# MSS_CTRL_MSS_CTRL_50D00000h register map
Vendor: Texas Instruments
Registers are 32-bit, read-only, reset values left out (the file's numbers can be read two ways) unless marked. A register's access mark holds for its fields unless they carry their own. Offsets are as the file gives them; [hi:lo] are bit positions; {n}, {i} and the like mark numbered series.

## MSS_CTRL (part 3 of 10)
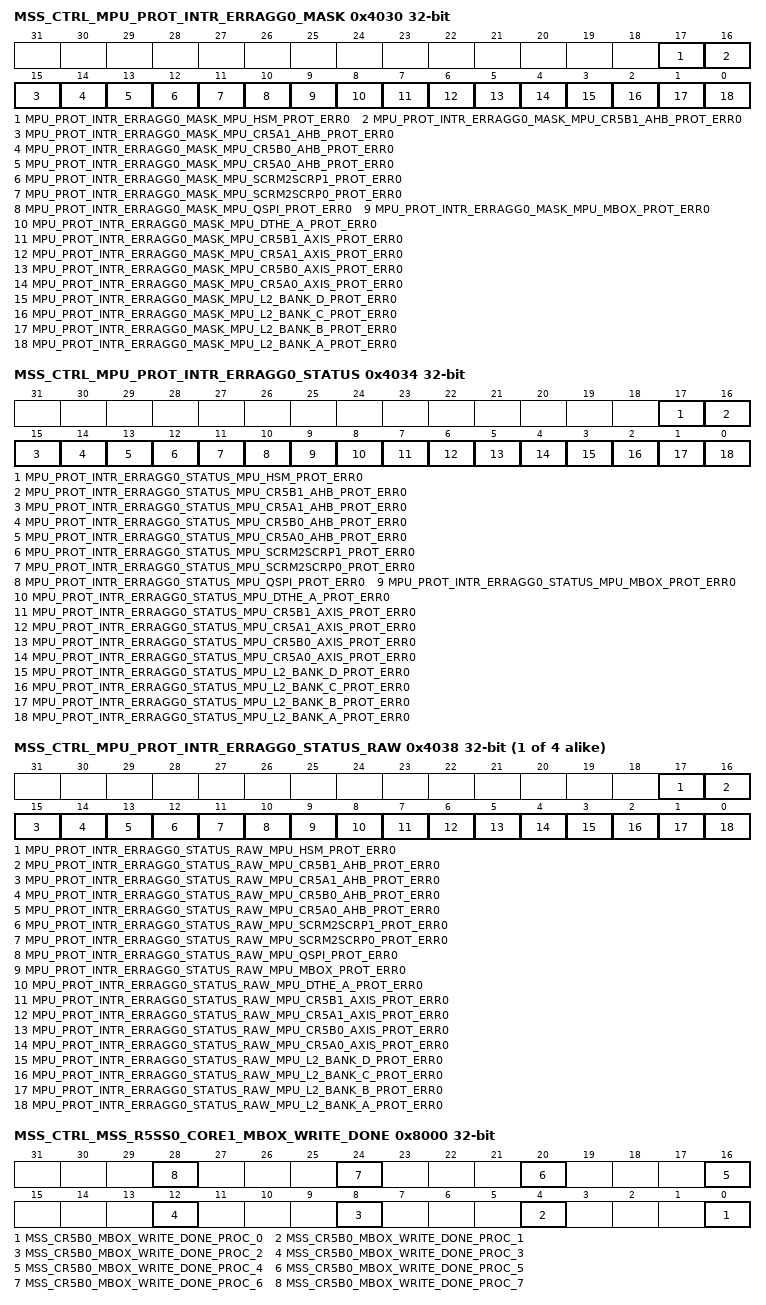
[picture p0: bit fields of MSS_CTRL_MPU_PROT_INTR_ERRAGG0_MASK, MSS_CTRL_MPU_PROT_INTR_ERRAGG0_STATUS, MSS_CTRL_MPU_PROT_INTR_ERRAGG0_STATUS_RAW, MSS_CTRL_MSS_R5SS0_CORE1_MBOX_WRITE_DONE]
0x4030 MSS_CTRL_MPU_PROT_INTR_ERRAGG0_MASK rw — This register Masks selected interrupt soures from generating MPU Protection Error Interrupt to R5SS0 CORE0 .
  [17] MPU_PROT_INTR_ERRAGG0_MASK_MPU_HSM_PROT_ERR0 — Mask Error from MPU_PROT_INTR to aggregated Error MPU_PROT_INTR_ERRAGG1'b1 : Error is Masked1'b0 : Error is Unmasked
  [16] MPU_PROT_INTR_ERRAGG0_MASK_MPU_CR5B1_AHB_PROT_ERR0 — Mask Error from MPU_PROT_INTR to aggregated Error MPU_PROT_INTR_ERRAGG1'b1 : Error is Masked1'b0 : Error is Unmasked
  [15] MPU_PROT_INTR_ERRAGG0_MASK_MPU_CR5A1_AHB_PROT_ERR0 — Mask Error from MPU_PROT_INTR to aggregated Error MPU_PROT_INTR_ERRAGG1'b1 : Error is Masked1'b0 : Error is Unmasked
  [14] MPU_PROT_INTR_ERRAGG0_MASK_MPU_CR5B0_AHB_PROT_ERR0 — Mask Error from MPU_PROT_INTR to aggregated Error MPU_PROT_INTR_ERRAGG1'b1 : Error is Masked1'b0 : Error is Unmasked
  [13] MPU_PROT_INTR_ERRAGG0_MASK_MPU_CR5A0_AHB_PROT_ERR0 — Mask Error from MPU_PROT_INTR to aggregated Error MPU_PROT_INTR_ERRAGG1'b1 : Error is Masked1'b0 : Error is Unmasked
  [12] MPU_PROT_INTR_ERRAGG0_MASK_MPU_SCRM2SCRP1_PROT_ERR0 — Mask Error from MPU_PROT_INTR to aggregated Error MPU_PROT_INTR_ERRAGG1'b1 : Error is Masked1'b0 : Error is Unmasked
  [11] MPU_PROT_INTR_ERRAGG0_MASK_MPU_SCRM2SCRP0_PROT_ERR0 — Mask Error from MPU_PROT_INTR to aggregated Error MPU_PROT_INTR_ERRAGG1'b1 : Error is Masked1'b0 : Error is Unmasked
  [10] MPU_PROT_INTR_ERRAGG0_MASK_MPU_QSPI_PROT_ERR0 — Mask Error from MPU_PROT_INTR to aggregated Error MPU_PROT_INTR_ERRAGG1'b1 : Error is Masked1'b0 : Error is Unmasked
  [9] MPU_PROT_INTR_ERRAGG0_MASK_MPU_MBOX_PROT_ERR0 — Mask Error from MPU_PROT_INTR to aggregated Error MPU_PROT_INTR_ERRAGG1'b1 : Error is Masked1'b0 : Error is Unmasked
  [8] MPU_PROT_INTR_ERRAGG0_MASK_MPU_DTHE_A_PROT_ERR0 — Mask Error from MPU_PROT_INTR to aggregated Error MPU_PROT_INTR_ERRAGG1'b1 : Error is Masked1'b0 : Error is Unmasked
  [7] MPU_PROT_INTR_ERRAGG0_MASK_MPU_CR5B1_AXIS_PROT_ERR0 — Mask Error from MPU_PROT_INTR to aggregated Error MPU_PROT_INTR_ERRAGG1'b1 : Error is Masked1'b0 : Error is Unmasked
  [6] MPU_PROT_INTR_ERRAGG0_MASK_MPU_CR5A1_AXIS_PROT_ERR0 — Mask Error from MPU_PROT_INTR to aggregated Error MPU_PROT_INTR_ERRAGG1'b1 : Error is Masked1'b0 : Error is Unmasked
  [5] MPU_PROT_INTR_ERRAGG0_MASK_MPU_CR5B0_AXIS_PROT_ERR0 — Mask Error from MPU_PROT_INTR to aggregated Error MPU_PROT_INTR_ERRAGG1'b1 : Error is Masked1'b0 : Error is Unmasked
  [4] MPU_PROT_INTR_ERRAGG0_MASK_MPU_CR5A0_AXIS_PROT_ERR0 — Mask Error from MPU_PROT_INTR to aggregated Error MPU_PROT_INTR_ERRAGG1'b1 : Error is Masked1'b0 : Error is Unmasked
  [3] MPU_PROT_INTR_ERRAGG0_MASK_MPU_L2_BANK_D_PROT_ERR0 — Mask Error from MPU_PROT_INTR to aggregated Error MPU_PROT_INTR_ERRAGG1'b1 : Error is Masked1'b0 : Error is Unmasked
  [2] MPU_PROT_INTR_ERRAGG0_MASK_MPU_L2_BANK_C_PROT_ERR0 — Mask Error from MPU_PROT_INTR to aggregated Error MPU_PROT_INTR_ERRAGG1'b1 : Error is Masked1'b0 : Error is Unmasked
  [1] MPU_PROT_INTR_ERRAGG0_MASK_MPU_L2_BANK_B_PROT_ERR0 — Mask Error from MPU_PROT_INTR to aggregated Error MPU_PROT_INTR_ERRAGG1'b1 : Error is Masked1'b0 : Error is Unmasked
  [0] MPU_PROT_INTR_ERRAGG0_MASK_MPU_L2_BANK_A_PROT_ERR0 — Mask Error from MPU_PROT_INTR to aggregated Error MPU_PROT_INTR_ERRAGG1'b1 : Error is Masked1'b0 : Error is Unmasked
0x4034 MSS_CTRL_MPU_PROT_INTR_ERRAGG0_STATUS rw — This register shows the Status of Unmasked MPU Protection Errors to R5SS0 Core0 .
  [17] MPU_PROT_INTR_ERRAGG0_STATUS_MPU_HSM_PROT_ERR0 — Status of Error from MPU_PROT_INTR. Set only if Interupt is unmasked in MPU_PROT_INTR_ERRAGG_MASKWrie 0x1 to clear this Error.
  [16] MPU_PROT_INTR_ERRAGG0_STATUS_MPU_CR5B1_AHB_PROT_ERR0 — Status of Error from MPU_PROT_INTR. Set only if Interupt is unmasked in MPU_PROT_INTR_ERRAGG_MASKWrie 0x1 to clear this Error.
  [15] MPU_PROT_INTR_ERRAGG0_STATUS_MPU_CR5A1_AHB_PROT_ERR0 — Status of Error from MPU_PROT_INTR. Set only if Interupt is unmasked in MPU_PROT_INTR_ERRAGG_MASKWrie 0x1 to clear this Error.
  [14] MPU_PROT_INTR_ERRAGG0_STATUS_MPU_CR5B0_AHB_PROT_ERR0 — Status of Error from MPU_PROT_INTR. Set only if Interupt is unmasked in MPU_PROT_INTR_ERRAGG_MASKWrie 0x1 to clear this Error.
  [13] MPU_PROT_INTR_ERRAGG0_STATUS_MPU_CR5A0_AHB_PROT_ERR0 — Status of Error from MPU_PROT_INTR. Set only if Interupt is unmasked in MPU_PROT_INTR_ERRAGG_MASKWrie 0x1 to clear this Error.
  [12] MPU_PROT_INTR_ERRAGG0_STATUS_MPU_SCRM2SCRP1_PROT_ERR0 — Status of Error from MPU_PROT_INTR. Set only if Interupt is unmasked in MPU_PROT_INTR_ERRAGG_MASKWrie 0x1 to clear this Error.
  [11] MPU_PROT_INTR_ERRAGG0_STATUS_MPU_SCRM2SCRP0_PROT_ERR0 — Status of Error from MPU_PROT_INTR. Set only if Interupt is unmasked in MPU_PROT_INTR_ERRAGG_MASKWrie 0x1 to clear this Error.
  [10] MPU_PROT_INTR_ERRAGG0_STATUS_MPU_QSPI_PROT_ERR0 — Status of Error from MPU_PROT_INTR. Set only if Interupt is unmasked in MPU_PROT_INTR_ERRAGG_MASKWrie 0x1 to clear this Error.
  [9] MPU_PROT_INTR_ERRAGG0_STATUS_MPU_MBOX_PROT_ERR0 — Status of Error from MPU_PROT_INTR. Set only if Interupt is unmasked in MPU_PROT_INTR_ERRAGG_MASKWrie 0x1 to clear this Error.
  [8] MPU_PROT_INTR_ERRAGG0_STATUS_MPU_DTHE_A_PROT_ERR0 — Status of Error from MPU_PROT_INTR. Set only if Interupt is unmasked in MPU_PROT_INTR_ERRAGG_MASKWrie 0x1 to clear this Error.
  [7] MPU_PROT_INTR_ERRAGG0_STATUS_MPU_CR5B1_AXIS_PROT_ERR0 — Status of Error from MPU_PROT_INTR. Set only if Interupt is unmasked in MPU_PROT_INTR_ERRAGG_MASKWrie 0x1 to clear this Error.
  [6] MPU_PROT_INTR_ERRAGG0_STATUS_MPU_CR5A1_AXIS_PROT_ERR0 — Status of Error from MPU_PROT_INTR. Set only if Interupt is unmasked in MPU_PROT_INTR_ERRAGG_MASKWrie 0x1 to clear this Error.
  [5] MPU_PROT_INTR_ERRAGG0_STATUS_MPU_CR5B0_AXIS_PROT_ERR0 — Status of Error from MPU_PROT_INTR. Set only if Interupt is unmasked in MPU_PROT_INTR_ERRAGG_MASKWrie 0x1 to clear this Error.
  [4] MPU_PROT_INTR_ERRAGG0_STATUS_MPU_CR5A0_AXIS_PROT_ERR0 — Status of Error from MPU_PROT_INTR. Set only if Interupt is unmasked in MPU_PROT_INTR_ERRAGG_MASKWrie 0x1 to clear this Error.
  [3] MPU_PROT_INTR_ERRAGG0_STATUS_MPU_L2_BANK_D_PROT_ERR0 — Status of Error from MPU_PROT_INTR. Set only if Interupt is unmasked in MPU_PROT_INTR_ERRAGG_MASKWrie 0x1 to clear this Error.
  [2] MPU_PROT_INTR_ERRAGG0_STATUS_MPU_L2_BANK_C_PROT_ERR0 — Status of Error from MPU_PROT_INTR. Set only if Interupt is unmasked in MPU_PROT_INTR_ERRAGG_MASKWrie 0x1 to clear this Error.
  [1] MPU_PROT_INTR_ERRAGG0_STATUS_MPU_L2_BANK_B_PROT_ERR0 — Status of Error from MPU_PROT_INTR. Set only if Interupt is unmasked in MPU_PROT_INTR_ERRAGG_MASKWrie 0x1 to clear this Error.
  [0] MPU_PROT_INTR_ERRAGG0_STATUS_MPU_L2_BANK_A_PROT_ERR0 — Status of Error from MPU_PROT_INTR. Set only if Interupt is unmasked in MPU_PROT_INTR_ERRAGG_MASKWrie 0x1 to clear this Error.
{0x4038+0x4000*i} MSS_CTRL_MPU_PROT_INTR_ERRAGG{i}_STATUS_RAW rw (i=0..3) — This register shows the Status of all MPU Protection Errors.
  [17] MPU_PROT_INTR_ERRAGG{i}_STATUS_RAW_MPU_HSM_PROT_ERR{i} — Raw Status of Error from MPU_PROT_INTR. Set irrespective if the Interupt is masked or unmasked in MPU_PROT_INTR_ERRAGG_MASK
  [16] MPU_PROT_INTR_ERRAGG{i}_STATUS_RAW_MPU_CR5B1_AHB_PROT_ERR{i} — Raw Status of Error from MPU_PROT_INTR. Set irrespective if the Interupt is masked or unmasked in MPU_PROT_INTR_ERRAGG_MASK
  [15] MPU_PROT_INTR_ERRAGG{i}_STATUS_RAW_MPU_CR5A1_AHB_PROT_ERR{i} — Raw Status of Error from MPU_PROT_INTR. Set irrespective if the Interupt is masked or unmasked in MPU_PROT_INTR_ERRAGG_MASK
  [14] MPU_PROT_INTR_ERRAGG{i}_STATUS_RAW_MPU_CR5B0_AHB_PROT_ERR{i} — Raw Status of Error from MPU_PROT_INTR. Set irrespective if the Interupt is masked or unmasked in MPU_PROT_INTR_ERRAGG_MASK
  [13] MPU_PROT_INTR_ERRAGG{i}_STATUS_RAW_MPU_CR5A0_AHB_PROT_ERR{i} — Raw Status of Error from MPU_PROT_INTR. Set irrespective if the Interupt is masked or unmasked in MPU_PROT_INTR_ERRAGG_MASK
  [12] MPU_PROT_INTR_ERRAGG{i}_STATUS_RAW_MPU_SCRM2SCRP1_PROT_ERR{i} — Raw Status of Error from MPU_PROT_INTR. Set irrespective if the Interupt is masked or unmasked in MPU_PROT_INTR_ERRAGG_MASK
  [11] MPU_PROT_INTR_ERRAGG{i}_STATUS_RAW_MPU_SCRM2SCRP0_PROT_ERR{i} — Raw Status of Error from MPU_PROT_INTR. Set irrespective if the Interupt is masked or unmasked in MPU_PROT_INTR_ERRAGG_MASK
  [10] MPU_PROT_INTR_ERRAGG{i}_STATUS_RAW_MPU_QSPI_PROT_ERR{i} — Raw Status of Error from MPU_PROT_INTR. Set irrespective if the Interupt is masked or unmasked in MPU_PROT_INTR_ERRAGG_MASK
  [9] MPU_PROT_INTR_ERRAGG{i}_STATUS_RAW_MPU_MBOX_PROT_ERR{i} — Raw Status of Error from MPU_PROT_INTR. Set irrespective if the Interupt is masked or unmasked in MPU_PROT_INTR_ERRAGG_MASK
  [8] MPU_PROT_INTR_ERRAGG{i}_STATUS_RAW_MPU_DTHE_A_PROT_ERR{i} — Raw Status of Error from MPU_PROT_INTR. Set irrespective if the Interupt is masked or unmasked in MPU_PROT_INTR_ERRAGG_MASK
  [7] MPU_PROT_INTR_ERRAGG{i}_STATUS_RAW_MPU_CR5B1_AXIS_PROT_ERR{i} — Raw Status of Error from MPU_PROT_INTR. Set irrespective if the Interupt is masked or unmasked in MPU_PROT_INTR_ERRAGG_MASK
  [6] MPU_PROT_INTR_ERRAGG{i}_STATUS_RAW_MPU_CR5A1_AXIS_PROT_ERR{i} — Raw Status of Error from MPU_PROT_INTR. Set irrespective if the Interupt is masked or unmasked in MPU_PROT_INTR_ERRAGG_MASK
  [5] MPU_PROT_INTR_ERRAGG{i}_STATUS_RAW_MPU_CR5B0_AXIS_PROT_ERR{i} — Raw Status of Error from MPU_PROT_INTR. Set irrespective if the Interupt is masked or unmasked in MPU_PROT_INTR_ERRAGG_MASK
  [4] MPU_PROT_INTR_ERRAGG{i}_STATUS_RAW_MPU_CR5A0_AXIS_PROT_ERR{i} — Raw Status of Error from MPU_PROT_INTR. Set irrespective if the Interupt is masked or unmasked in MPU_PROT_INTR_ERRAGG_MASK
  [3] MPU_PROT_INTR_ERRAGG{i}_STATUS_RAW_MPU_L2_BANK_D_PROT_ERR{i} — Raw Status of Error from MPU_PROT_INTR. Set irrespective if the Interupt is masked or unmasked in MPU_PROT_INTR_ERRAGG_MASK
  [2] MPU_PROT_INTR_ERRAGG{i}_STATUS_RAW_MPU_L2_BANK_C_PROT_ERR{i} — Raw Status of Error from MPU_PROT_INTR. Set irrespective if the Interupt is masked or unmasked in MPU_PROT_INTR_ERRAGG_MASK
  [1] MPU_PROT_INTR_ERRAGG{i}_STATUS_RAW_MPU_L2_BANK_B_PROT_ERR{i} — Raw Status of Error from MPU_PROT_INTR. Set irrespective if the Interupt is masked or unmasked in MPU_PROT_INTR_ERRAGG_MASK
  [0] MPU_PROT_INTR_ERRAGG{i}_STATUS_RAW_MPU_L2_BANK_A_PROT_ERR{i} — Raw Status of Error from MPU_PROT_INTR. Set irrespective if the Interupt is masked or unmasked in MPU_PROT_INTR_ERRAGG_MASK
0x8000 MSS_CTRL_MSS_R5SS0_CORE1_MBOX_WRITE_DONE rw — This register is used by R5SS0 Core 1 to generate Mailbox interrupt to Recipent CPU.
  [4n] MSS_CR5B0_MBOX_WRITE_DONE_PROC_{n} (n=0..7) — Write pulse bit field:This register should be written once finishing Writing into the mailbox memory of processor {n}
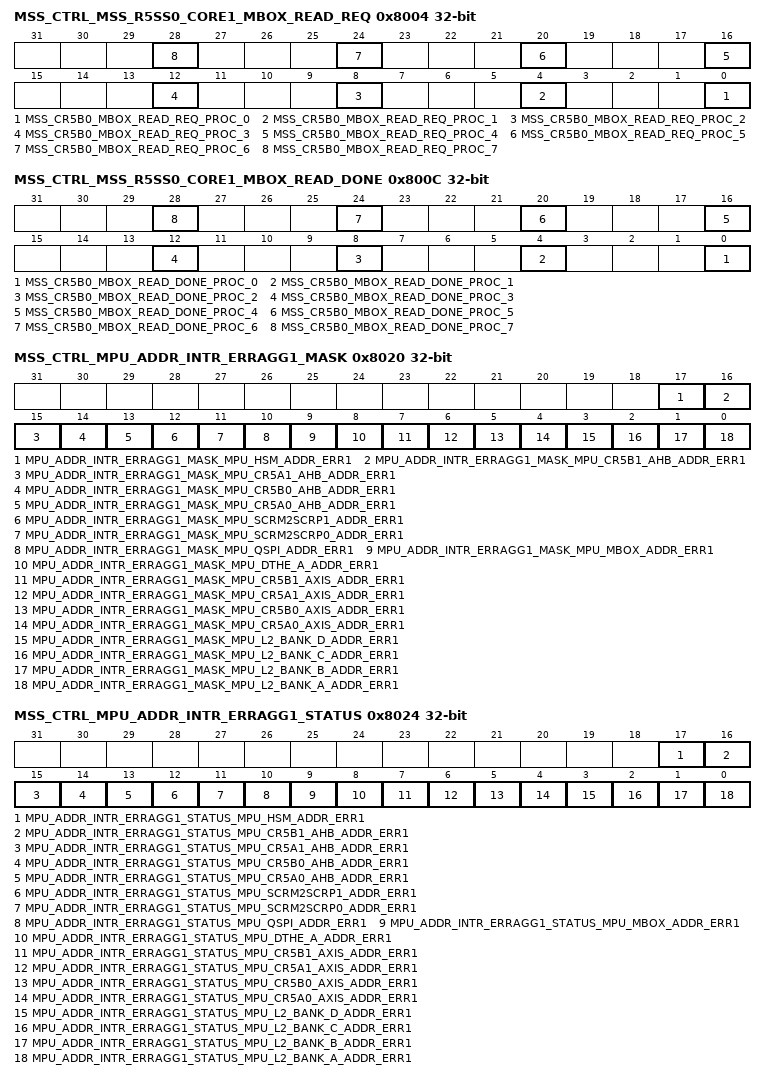
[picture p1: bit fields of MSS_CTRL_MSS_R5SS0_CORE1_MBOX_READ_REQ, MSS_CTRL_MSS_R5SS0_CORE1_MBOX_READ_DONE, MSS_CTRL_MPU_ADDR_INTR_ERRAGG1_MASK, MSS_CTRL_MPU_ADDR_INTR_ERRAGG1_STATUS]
0x8004 MSS_CTRL_MSS_R5SS0_CORE1_MBOX_READ_REQ rw — This register is used by R5SS0 Core 1 to know the Sender of Mailbox Interrupt as well as clear it.
  [4n] MSS_CR5B0_MBOX_READ_REQ_PROC_{n} (n=0..7) — This is request from processor {n} to mss_CR5B. Requesting it to read from mailbox.
0x8008 MSS_CTRL_MSS_R5SS0_CORE1_MBOX_READ_DONE_ACK rw — This register is used by R5SS0 Core 1 to generate Mailbox Read acknowledgement to the Sender CPU.
  [7:0] MSS_CR5B0_MBOX_READ_DONE_ACK_PROC — Write pulse bit field:For bits 0 to7:Wrting1'b1 : Generates pulse interrupt to corresponding proc from MSS_CR5
0x800C MSS_CTRL_MSS_R5SS0_CORE1_MBOX_READ_DONE rw — This register is used by R5SS0 Core 1 to know that the Receiver CPU has read the Mailbox and Acked. It is also used to clear the Read Done Interrupt.
  [4n] MSS_CR5B0_MBOX_READ_DONE_PROC_{n} (n=0..7) — This register should be written once finishing Reading from proc{n}'s mailbox written by CR5B
0x8010 MSS_CTRL_MSS_SW_INT_R5SS0_CORE1 rw — This Register is used to generate a S/W Triggered Interrupt to R5SS0 Core1.
  [0] MSS_SW_INT_R5SS0_CORE1_PULSE — Write_pulse bit field:Writing 1'b1 to each bit will trigger MSS_SW_INT respectively to CR5A/B.
0x8020 MSS_CTRL_MPU_ADDR_INTR_ERRAGG1_MASK rw — This register Masks selected interrupt soures from generating MPU Address Error Interrupt to R5SS0 CORE1 .
  [17] MPU_ADDR_INTR_ERRAGG1_MASK_MPU_HSM_ADDR_ERR1 — Mask Error from MPU_ADDR_INTR to aggregated Error MPU_ADDR_INTR_ERRAGG1'b1 : Error is Masked1'b0 : Error is Unmasked
  [16] MPU_ADDR_INTR_ERRAGG1_MASK_MPU_CR5B1_AHB_ADDR_ERR1 — Mask Error from MPU_ADDR_INTR to aggregated Error MPU_ADDR_INTR_ERRAGG1'b1 : Error is Masked1'b0 : Error is Unmasked
  [15] MPU_ADDR_INTR_ERRAGG1_MASK_MPU_CR5A1_AHB_ADDR_ERR1 — Mask Error from MPU_ADDR_INTR to aggregated Error MPU_ADDR_INTR_ERRAGG1'b1 : Error is Masked1'b0 : Error is Unmasked
  [14] MPU_ADDR_INTR_ERRAGG1_MASK_MPU_CR5B0_AHB_ADDR_ERR1 — Mask Error from MPU_ADDR_INTR to aggregated Error MPU_ADDR_INTR_ERRAGG1'b1 : Error is Masked1'b0 : Error is Unmasked
  [13] MPU_ADDR_INTR_ERRAGG1_MASK_MPU_CR5A0_AHB_ADDR_ERR1 — Mask Error from MPU_ADDR_INTR to aggregated Error MPU_ADDR_INTR_ERRAGG1'b1 : Error is Masked1'b0 : Error is Unmasked
  [12] MPU_ADDR_INTR_ERRAGG1_MASK_MPU_SCRM2SCRP1_ADDR_ERR1 — Mask Error from MPU_ADDR_INTR to aggregated Error MPU_ADDR_INTR_ERRAGG1'b1 : Error is Masked1'b0 : Error is Unmasked
  [11] MPU_ADDR_INTR_ERRAGG1_MASK_MPU_SCRM2SCRP0_ADDR_ERR1 — Mask Error from MPU_ADDR_INTR to aggregated Error MPU_ADDR_INTR_ERRAGG1'b1 : Error is Masked1'b0 : Error is Unmasked
  [10] MPU_ADDR_INTR_ERRAGG1_MASK_MPU_QSPI_ADDR_ERR1 — Mask Error from MPU_ADDR_INTR to aggregated Error MPU_ADDR_INTR_ERRAGG1'b1 : Error is Masked1'b0 : Error is Unmasked
  [9] MPU_ADDR_INTR_ERRAGG1_MASK_MPU_MBOX_ADDR_ERR1 — Mask Error from MPU_ADDR_INTR to aggregated Error MPU_ADDR_INTR_ERRAGG1'b1 : Error is Masked1'b0 : Error is Unmasked
  [8] MPU_ADDR_INTR_ERRAGG1_MASK_MPU_DTHE_A_ADDR_ERR1 — Mask Error from MPU_ADDR_INTR to aggregated Error MPU_ADDR_INTR_ERRAGG1'b1 : Error is Masked1'b0 : Error is Unmasked
  [7] MPU_ADDR_INTR_ERRAGG1_MASK_MPU_CR5B1_AXIS_ADDR_ERR1 — Mask Error from MPU_ADDR_INTR to aggregated Error MPU_ADDR_INTR_ERRAGG1'b1 : Error is Masked1'b0 : Error is Unmasked
  [6] MPU_ADDR_INTR_ERRAGG1_MASK_MPU_CR5A1_AXIS_ADDR_ERR1 — Mask Error from MPU_ADDR_INTR to aggregated Error MPU_ADDR_INTR_ERRAGG1'b1 : Error is Masked1'b0 : Error is Unmasked
  [5] MPU_ADDR_INTR_ERRAGG1_MASK_MPU_CR5B0_AXIS_ADDR_ERR1 — Mask Error from MPU_ADDR_INTR to aggregated Error MPU_ADDR_INTR_ERRAGG1'b1 : Error is Masked1'b0 : Error is Unmasked
  [4] MPU_ADDR_INTR_ERRAGG1_MASK_MPU_CR5A0_AXIS_ADDR_ERR1 — Mask Error from MPU_ADDR_INTR to aggregated Error MPU_ADDR_INTR_ERRAGG1'b1 : Error is Masked1'b0 : Error is Unmasked
  [3] MPU_ADDR_INTR_ERRAGG1_MASK_MPU_L2_BANK_D_ADDR_ERR1 — Mask Error from MPU_ADDR_INTR to aggregated Error MPU_ADDR_INTR_ERRAGG1'b1 : Error is Masked1'b0 : Error is Unmasked
  [2] MPU_ADDR_INTR_ERRAGG1_MASK_MPU_L2_BANK_C_ADDR_ERR1 — Mask Error from MPU_ADDR_INTR to aggregated Error MPU_ADDR_INTR_ERRAGG1'b1 : Error is Masked1'b0 : Error is Unmasked
  [1] MPU_ADDR_INTR_ERRAGG1_MASK_MPU_L2_BANK_B_ADDR_ERR1 — Mask Error from MPU_ADDR_INTR to aggregated Error MPU_ADDR_INTR_ERRAGG1'b1 : Error is Masked1'b0 : Error is Unmasked
  [0] MPU_ADDR_INTR_ERRAGG1_MASK_MPU_L2_BANK_A_ADDR_ERR1 — Mask Error from MPU_ADDR_INTR to aggregated Error MPU_ADDR_INTR_ERRAGG1'b1 : Error is Masked1'b0 : Error is Unmasked
0x8024 MSS_CTRL_MPU_ADDR_INTR_ERRAGG1_STATUS rw — This register shows the Status of Unmasked MPU Address Errors to R5SS0 CORE1 .
  [17] MPU_ADDR_INTR_ERRAGG1_STATUS_MPU_HSM_ADDR_ERR1 — Status of Error from MPU_ADDR_INTR. Set only if Interupt is unmasked in MPU_ADDR_INTR_ERRAGG_MASKWrie 0x1 to clear this Error.
  [16] MPU_ADDR_INTR_ERRAGG1_STATUS_MPU_CR5B1_AHB_ADDR_ERR1 — Status of Error from MPU_ADDR_INTR. Set only if Interupt is unmasked in MPU_ADDR_INTR_ERRAGG_MASKWrie 0x1 to clear this Error.
  [15] MPU_ADDR_INTR_ERRAGG1_STATUS_MPU_CR5A1_AHB_ADDR_ERR1 — Status of Error from MPU_ADDR_INTR. Set only if Interupt is unmasked in MPU_ADDR_INTR_ERRAGG_MASKWrie 0x1 to clear this Error.
  [14] MPU_ADDR_INTR_ERRAGG1_STATUS_MPU_CR5B0_AHB_ADDR_ERR1 — Status of Error from MPU_ADDR_INTR. Set only if Interupt is unmasked in MPU_ADDR_INTR_ERRAGG_MASKWrie 0x1 to clear this Error.
  [13] MPU_ADDR_INTR_ERRAGG1_STATUS_MPU_CR5A0_AHB_ADDR_ERR1 — Status of Error from MPU_ADDR_INTR. Set only if Interupt is unmasked in MPU_ADDR_INTR_ERRAGG_MASKWrie 0x1 to clear this Error.
  [12] MPU_ADDR_INTR_ERRAGG1_STATUS_MPU_SCRM2SCRP1_ADDR_ERR1 — Status of Error from MPU_ADDR_INTR. Set only if Interupt is unmasked in MPU_ADDR_INTR_ERRAGG_MASKWrie 0x1 to clear this Error.
  [11] MPU_ADDR_INTR_ERRAGG1_STATUS_MPU_SCRM2SCRP0_ADDR_ERR1 — Status of Error from MPU_ADDR_INTR. Set only if Interupt is unmasked in MPU_ADDR_INTR_ERRAGG_MASKWrie 0x1 to clear this Error.
  [10] MPU_ADDR_INTR_ERRAGG1_STATUS_MPU_QSPI_ADDR_ERR1 — Status of Error from MPU_ADDR_INTR. Set only if Interupt is unmasked in MPU_ADDR_INTR_ERRAGG_MASKWrie 0x1 to clear this Error.
  [9] MPU_ADDR_INTR_ERRAGG1_STATUS_MPU_MBOX_ADDR_ERR1 — Status of Error from MPU_ADDR_INTR. Set only if Interupt is unmasked in MPU_ADDR_INTR_ERRAGG_MASKWrie 0x1 to clear this Error.
  [8] MPU_ADDR_INTR_ERRAGG1_STATUS_MPU_DTHE_A_ADDR_ERR1 — Status of Error from MPU_ADDR_INTR. Set only if Interupt is unmasked in MPU_ADDR_INTR_ERRAGG_MASKWrie 0x1 to clear this Error.
  [7] MPU_ADDR_INTR_ERRAGG1_STATUS_MPU_CR5B1_AXIS_ADDR_ERR1 — Status of Error from MPU_ADDR_INTR. Set only if Interupt is unmasked in MPU_ADDR_INTR_ERRAGG_MASKWrie 0x1 to clear this Error.
  [6] MPU_ADDR_INTR_ERRAGG1_STATUS_MPU_CR5A1_AXIS_ADDR_ERR1 — Status of Error from MPU_ADDR_INTR. Set only if Interupt is unmasked in MPU_ADDR_INTR_ERRAGG_MASKWrie 0x1 to clear this Error.
  [5] MPU_ADDR_INTR_ERRAGG1_STATUS_MPU_CR5B0_AXIS_ADDR_ERR1 — Status of Error from MPU_ADDR_INTR. Set only if Interupt is unmasked in MPU_ADDR_INTR_ERRAGG_MASKWrie 0x1 to clear this Error.
  [4] MPU_ADDR_INTR_ERRAGG1_STATUS_MPU_CR5A0_AXIS_ADDR_ERR1 — Status of Error from MPU_ADDR_INTR. Set only if Interupt is unmasked in MPU_ADDR_INTR_ERRAGG_MASKWrie 0x1 to clear this Error.
  [3] MPU_ADDR_INTR_ERRAGG1_STATUS_MPU_L2_BANK_D_ADDR_ERR1 — Status of Error from MPU_ADDR_INTR. Set only if Interupt is unmasked in MPU_ADDR_INTR_ERRAGG_MASKWrie 0x1 to clear this Error.
  [2] MPU_ADDR_INTR_ERRAGG1_STATUS_MPU_L2_BANK_C_ADDR_ERR1 — Status of Error from MPU_ADDR_INTR. Set only if Interupt is unmasked in MPU_ADDR_INTR_ERRAGG_MASKWrie 0x1 to clear this Error.
  [1] MPU_ADDR_INTR_ERRAGG1_STATUS_MPU_L2_BANK_B_ADDR_ERR1 — Status of Error from MPU_ADDR_INTR. Set only if Interupt is unmasked in MPU_ADDR_INTR_ERRAGG_MASKWrie 0x1 to clear this Error.
  [0] MPU_ADDR_INTR_ERRAGG1_STATUS_MPU_L2_BANK_A_ADDR_ERR1 — Status of Error from MPU_ADDR_INTR. Set only if Interupt is unmasked in MPU_ADDR_INTR_ERRAGG_MASKWrie 0x1 to clear this Error.
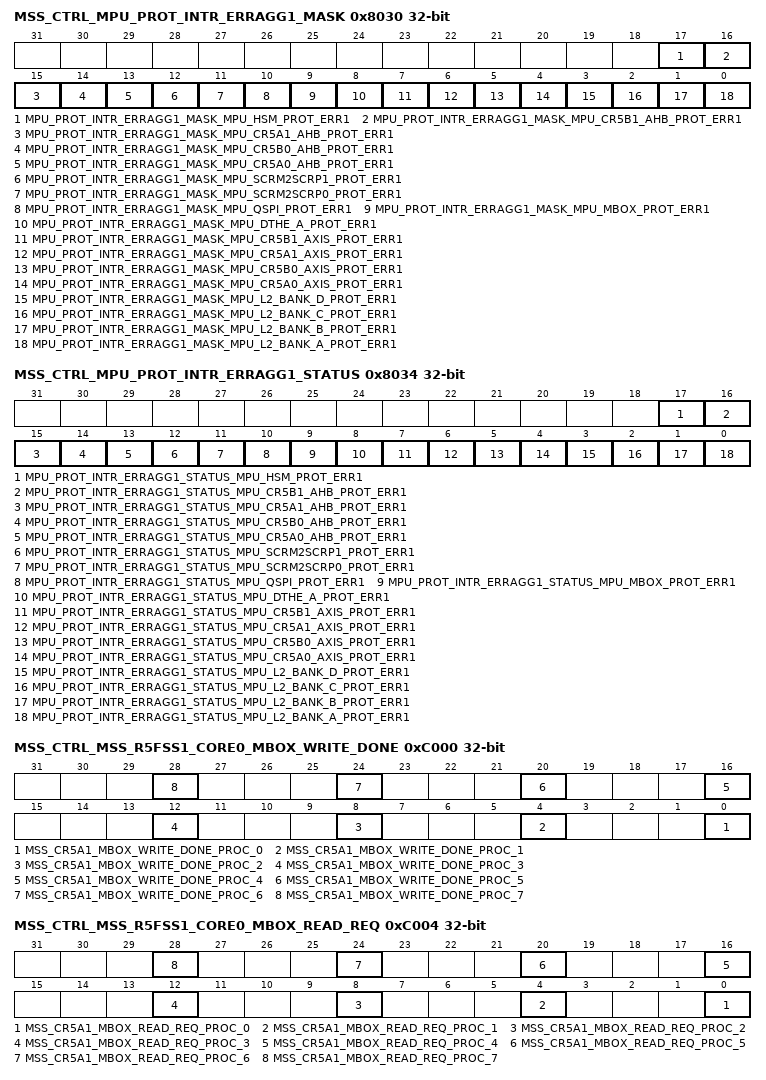
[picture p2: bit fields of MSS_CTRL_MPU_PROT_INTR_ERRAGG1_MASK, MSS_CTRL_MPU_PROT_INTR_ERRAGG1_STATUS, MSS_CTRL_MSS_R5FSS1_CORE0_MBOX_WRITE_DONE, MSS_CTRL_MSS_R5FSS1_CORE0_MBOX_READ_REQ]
0x8030 MSS_CTRL_MPU_PROT_INTR_ERRAGG1_MASK rw — This register Masks selected interrupt soures from generating MPU Protection Error Interrupt to R5SS0 CORE1 .
  [17] MPU_PROT_INTR_ERRAGG1_MASK_MPU_HSM_PROT_ERR1 — Mask Error from MPU_PROT_INTR to aggregated Error MPU_PROT_INTR_ERRAGG1'b1 : Error is Masked1'b0 : Error is Unmasked
  [16] MPU_PROT_INTR_ERRAGG1_MASK_MPU_CR5B1_AHB_PROT_ERR1 — Mask Error from MPU_PROT_INTR to aggregated Error MPU_PROT_INTR_ERRAGG1'b1 : Error is Masked1'b0 : Error is Unmasked
  [15] MPU_PROT_INTR_ERRAGG1_MASK_MPU_CR5A1_AHB_PROT_ERR1 — Mask Error from MPU_PROT_INTR to aggregated Error MPU_PROT_INTR_ERRAGG1'b1 : Error is Masked1'b0 : Error is Unmasked
  [14] MPU_PROT_INTR_ERRAGG1_MASK_MPU_CR5B0_AHB_PROT_ERR1 — Mask Error from MPU_PROT_INTR to aggregated Error MPU_PROT_INTR_ERRAGG1'b1 : Error is Masked1'b0 : Error is Unmasked
  [13] MPU_PROT_INTR_ERRAGG1_MASK_MPU_CR5A0_AHB_PROT_ERR1 — Mask Error from MPU_PROT_INTR to aggregated Error MPU_PROT_INTR_ERRAGG1'b1 : Error is Masked1'b0 : Error is Unmasked
  [12] MPU_PROT_INTR_ERRAGG1_MASK_MPU_SCRM2SCRP1_PROT_ERR1 — Mask Error from MPU_PROT_INTR to aggregated Error MPU_PROT_INTR_ERRAGG1'b1 : Error is Masked1'b0 : Error is Unmasked
  [11] MPU_PROT_INTR_ERRAGG1_MASK_MPU_SCRM2SCRP0_PROT_ERR1 — Mask Error from MPU_PROT_INTR to aggregated Error MPU_PROT_INTR_ERRAGG1'b1 : Error is Masked1'b0 : Error is Unmasked
  [10] MPU_PROT_INTR_ERRAGG1_MASK_MPU_QSPI_PROT_ERR1 — Mask Error from MPU_PROT_INTR to aggregated Error MPU_PROT_INTR_ERRAGG1'b1 : Error is Masked1'b0 : Error is Unmasked
  [9] MPU_PROT_INTR_ERRAGG1_MASK_MPU_MBOX_PROT_ERR1 — Mask Error from MPU_PROT_INTR to aggregated Error MPU_PROT_INTR_ERRAGG1'b1 : Error is Masked1'b0 : Error is Unmasked
  [8] MPU_PROT_INTR_ERRAGG1_MASK_MPU_DTHE_A_PROT_ERR1 — Mask Error from MPU_PROT_INTR to aggregated Error MPU_PROT_INTR_ERRAGG1'b1 : Error is Masked1'b0 : Error is Unmasked
  [7] MPU_PROT_INTR_ERRAGG1_MASK_MPU_CR5B1_AXIS_PROT_ERR1 — Mask Error from MPU_PROT_INTR to aggregated Error MPU_PROT_INTR_ERRAGG1'b1 : Error is Masked1'b0 : Error is Unmasked
  [6] MPU_PROT_INTR_ERRAGG1_MASK_MPU_CR5A1_AXIS_PROT_ERR1 — Mask Error from MPU_PROT_INTR to aggregated Error MPU_PROT_INTR_ERRAGG1'b1 : Error is Masked1'b0 : Error is Unmasked
  [5] MPU_PROT_INTR_ERRAGG1_MASK_MPU_CR5B0_AXIS_PROT_ERR1 — Mask Error from MPU_PROT_INTR to aggregated Error MPU_PROT_INTR_ERRAGG1'b1 : Error is Masked1'b0 : Error is Unmasked
  [4] MPU_PROT_INTR_ERRAGG1_MASK_MPU_CR5A0_AXIS_PROT_ERR1 — Mask Error from MPU_PROT_INTR to aggregated Error MPU_PROT_INTR_ERRAGG1'b1 : Error is Masked1'b0 : Error is Unmasked
  [3] MPU_PROT_INTR_ERRAGG1_MASK_MPU_L2_BANK_D_PROT_ERR1 — Mask Error from MPU_PROT_INTR to aggregated Error MPU_PROT_INTR_ERRAGG1'b1 : Error is Masked1'b0 : Error is Unmasked
  [2] MPU_PROT_INTR_ERRAGG1_MASK_MPU_L2_BANK_C_PROT_ERR1 — Mask Error from MPU_PROT_INTR to aggregated Error MPU_PROT_INTR_ERRAGG1'b1 : Error is Masked1'b0 : Error is Unmasked
  [1] MPU_PROT_INTR_ERRAGG1_MASK_MPU_L2_BANK_B_PROT_ERR1 — Mask Error from MPU_PROT_INTR to aggregated Error MPU_PROT_INTR_ERRAGG1'b1 : Error is Masked1'b0 : Error is Unmasked
  [0] MPU_PROT_INTR_ERRAGG1_MASK_MPU_L2_BANK_A_PROT_ERR1 — Mask Error from MPU_PROT_INTR to aggregated Error MPU_PROT_INTR_ERRAGG1'b1 : Error is Masked1'b0 : Error is Unmasked
0x8034 MSS_CTRL_MPU_PROT_INTR_ERRAGG1_STATUS rw — This register shows the Status of Unmasked MPU Protection Errors to R5SS0 CORE1 .
  [17] MPU_PROT_INTR_ERRAGG1_STATUS_MPU_HSM_PROT_ERR1 — Status of Error from MPU_PROT_INTR. Set only if Interupt is unmasked in MPU_PROT_INTR_ERRAGG_MASKWrie 0x1 to clear this Error.
  [16] MPU_PROT_INTR_ERRAGG1_STATUS_MPU_CR5B1_AHB_PROT_ERR1 — Status of Error from MPU_PROT_INTR. Set only if Interupt is unmasked in MPU_PROT_INTR_ERRAGG_MASKWrie 0x1 to clear this Error.
  [15] MPU_PROT_INTR_ERRAGG1_STATUS_MPU_CR5A1_AHB_PROT_ERR1 — Status of Error from MPU_PROT_INTR. Set only if Interupt is unmasked in MPU_PROT_INTR_ERRAGG_MASKWrie 0x1 to clear this Error.
  [14] MPU_PROT_INTR_ERRAGG1_STATUS_MPU_CR5B0_AHB_PROT_ERR1 — Status of Error from MPU_PROT_INTR. Set only if Interupt is unmasked in MPU_PROT_INTR_ERRAGG_MASKWrie 0x1 to clear this Error.
  [13] MPU_PROT_INTR_ERRAGG1_STATUS_MPU_CR5A0_AHB_PROT_ERR1 — Status of Error from MPU_PROT_INTR. Set only if Interupt is unmasked in MPU_PROT_INTR_ERRAGG_MASKWrie 0x1 to clear this Error.
  [12] MPU_PROT_INTR_ERRAGG1_STATUS_MPU_SCRM2SCRP1_PROT_ERR1 — Status of Error from MPU_PROT_INTR. Set only if Interupt is unmasked in MPU_PROT_INTR_ERRAGG_MASKWrie 0x1 to clear this Error.
  [11] MPU_PROT_INTR_ERRAGG1_STATUS_MPU_SCRM2SCRP0_PROT_ERR1 — Status of Error from MPU_PROT_INTR. Set only if Interupt is unmasked in MPU_PROT_INTR_ERRAGG_MASKWrie 0x1 to clear this Error.
  [10] MPU_PROT_INTR_ERRAGG1_STATUS_MPU_QSPI_PROT_ERR1 — Status of Error from MPU_PROT_INTR. Set only if Interupt is unmasked in MPU_PROT_INTR_ERRAGG_MASKWrie 0x1 to clear this Error.
  [9] MPU_PROT_INTR_ERRAGG1_STATUS_MPU_MBOX_PROT_ERR1 — Status of Error from MPU_PROT_INTR. Set only if Interupt is unmasked in MPU_PROT_INTR_ERRAGG_MASKWrie 0x1 to clear this Error.
  [8] MPU_PROT_INTR_ERRAGG1_STATUS_MPU_DTHE_A_PROT_ERR1 — Status of Error from MPU_PROT_INTR. Set only if Interupt is unmasked in MPU_PROT_INTR_ERRAGG_MASKWrie 0x1 to clear this Error.
  [7] MPU_PROT_INTR_ERRAGG1_STATUS_MPU_CR5B1_AXIS_PROT_ERR1 — Status of Error from MPU_PROT_INTR. Set only if Interupt is unmasked in MPU_PROT_INTR_ERRAGG_MASKWrie 0x1 to clear this Error.
  [6] MPU_PROT_INTR_ERRAGG1_STATUS_MPU_CR5A1_AXIS_PROT_ERR1 — Status of Error from MPU_PROT_INTR. Set only if Interupt is unmasked in MPU_PROT_INTR_ERRAGG_MASKWrie 0x1 to clear this Error.
  [5] MPU_PROT_INTR_ERRAGG1_STATUS_MPU_CR5B0_AXIS_PROT_ERR1 — Status of Error from MPU_PROT_INTR. Set only if Interupt is unmasked in MPU_PROT_INTR_ERRAGG_MASKWrie 0x1 to clear this Error.
  [4] MPU_PROT_INTR_ERRAGG1_STATUS_MPU_CR5A0_AXIS_PROT_ERR1 — Status of Error from MPU_PROT_INTR. Set only if Interupt is unmasked in MPU_PROT_INTR_ERRAGG_MASKWrie 0x1 to clear this Error.
  [3] MPU_PROT_INTR_ERRAGG1_STATUS_MPU_L2_BANK_D_PROT_ERR1 — Status of Error from MPU_PROT_INTR. Set only if Interupt is unmasked in MPU_PROT_INTR_ERRAGG_MASKWrie 0x1 to clear this Error.
  [2] MPU_PROT_INTR_ERRAGG1_STATUS_MPU_L2_BANK_C_PROT_ERR1 — Status of Error from MPU_PROT_INTR. Set only if Interupt is unmasked in MPU_PROT_INTR_ERRAGG_MASKWrie 0x1 to clear this Error.
  [1] MPU_PROT_INTR_ERRAGG1_STATUS_MPU_L2_BANK_B_PROT_ERR1 — Status of Error from MPU_PROT_INTR. Set only if Interupt is unmasked in MPU_PROT_INTR_ERRAGG_MASKWrie 0x1 to clear this Error.
  [0] MPU_PROT_INTR_ERRAGG1_STATUS_MPU_L2_BANK_A_PROT_ERR1 — Status of Error from MPU_PROT_INTR. Set only if Interupt is unmasked in MPU_PROT_INTR_ERRAGG_MASKWrie 0x1 to clear this Error.
0xC000 MSS_CTRL_MSS_R5FSS1_CORE0_MBOX_WRITE_DONE rw — This register is used by R5SS1 Core 0 to generate Mailbox interrupt to Recipent CPU.
  [4n] MSS_CR5A1_MBOX_WRITE_DONE_PROC_{n} (n=0..7) — Write pulse bit field:This register should be written once finishing Writing into the mailbox memory of processor {n}
0xC004 MSS_CTRL_MSS_R5FSS1_CORE0_MBOX_READ_REQ rw — This register is used by R5SS1 Core 0 to know the Sender of Mailbox Interrupt as well as clear it.
  [4n] MSS_CR5A1_MBOX_READ_REQ_PROC_{n} (n=0..7) — This is request from processor {n} to mss_cr5a. Requesting it to read from mailbox.
0xC008 MSS_CTRL_MSS_R5FSS1_CORE0_MBOX_READ_DONE_ACK rw — This register is used by R5SS1 Core 0 to generate Mailbox Read acknowledgement to the Sender CPU.
  [7:0] MSS_CR5A1_MBOX_READ_DONE_ACK_PROC — Write pulse bit field:For bits 0 to7:Wrting1'b1 : Generates pulse interrupt to corresponding proc from MSS_CR5
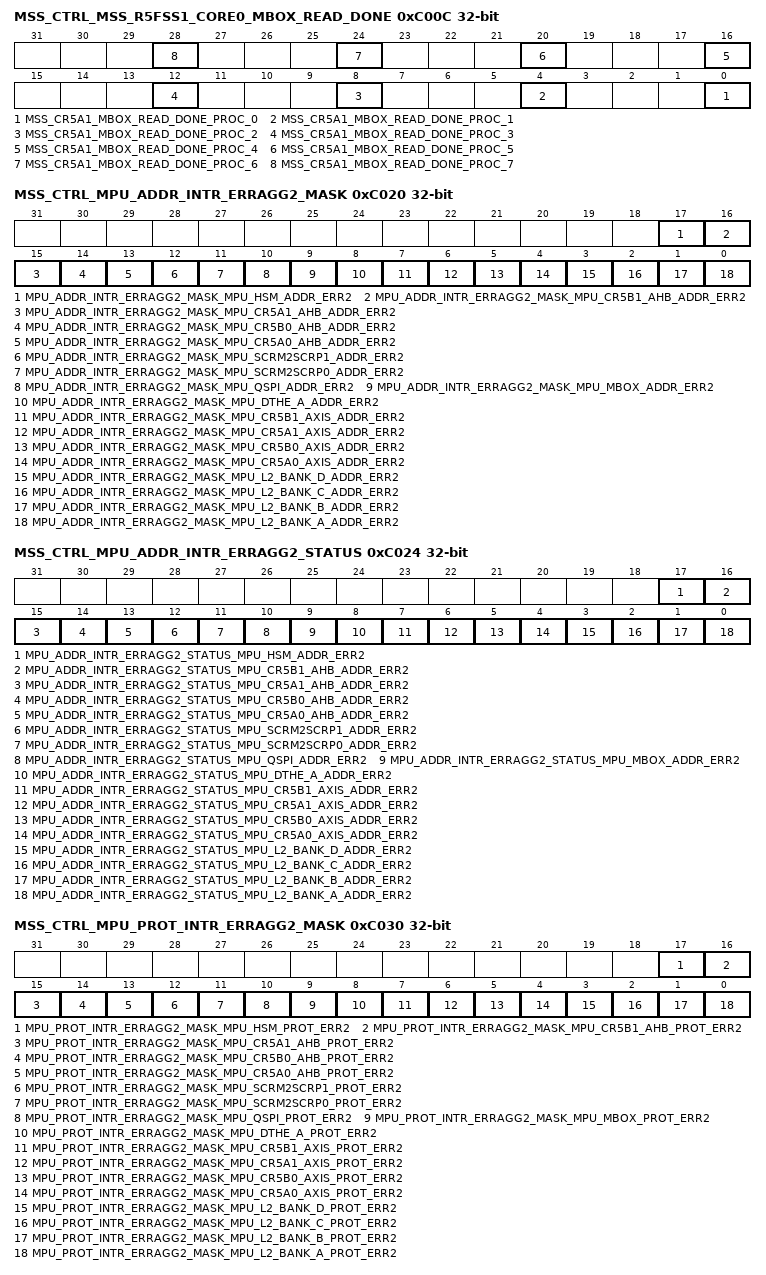
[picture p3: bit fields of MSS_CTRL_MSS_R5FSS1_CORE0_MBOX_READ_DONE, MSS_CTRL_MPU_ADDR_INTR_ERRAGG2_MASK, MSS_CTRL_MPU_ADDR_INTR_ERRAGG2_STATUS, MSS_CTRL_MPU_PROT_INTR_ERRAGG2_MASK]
0xC00C MSS_CTRL_MSS_R5FSS1_CORE0_MBOX_READ_DONE rw — This register is used by R5SS1 Core 0 to know that the Receiver CPU has read the Mailbox and Acked. It is also used to clear the Read Done Interrupt.
  [4n] MSS_CR5A1_MBOX_READ_DONE_PROC_{n} (n=0..7) — This register should be written once finishing Reading from proc{n}'s mailbox written by CR5A
0xC010 MSS_CTRL_MSS_SW_INT_R5SS1_CORE0 rw — This Register is used to generate a S/W Triggered Interrupt to R5SS1 Core0.
  [0] MSS_SW_INT_R5SS1_CORE0_PULSE — Write_pulse bit field:Writing 1'b1 to each bit will trigger MSS_SW_INT respectively to CR5A/B.
0xC020 MSS_CTRL_MPU_ADDR_INTR_ERRAGG2_MASK rw — This register Masks selected interrupt soures from generating MPU Address Error Interrupt to R5SS1 CORE0 .
  [17] MPU_ADDR_INTR_ERRAGG2_MASK_MPU_HSM_ADDR_ERR2 — Mask Error from MPU_ADDR_INTR to aggregated Error MPU_ADDR_INTR_ERRAGG1'b1 : Error is Masked1'b0 : Error is Unmasked
  [16] MPU_ADDR_INTR_ERRAGG2_MASK_MPU_CR5B1_AHB_ADDR_ERR2 — Mask Error from MPU_ADDR_INTR to aggregated Error MPU_ADDR_INTR_ERRAGG1'b1 : Error is Masked1'b0 : Error is Unmasked
  [15] MPU_ADDR_INTR_ERRAGG2_MASK_MPU_CR5A1_AHB_ADDR_ERR2 — Mask Error from MPU_ADDR_INTR to aggregated Error MPU_ADDR_INTR_ERRAGG1'b1 : Error is Masked1'b0 : Error is Unmasked
  [14] MPU_ADDR_INTR_ERRAGG2_MASK_MPU_CR5B0_AHB_ADDR_ERR2 — Mask Error from MPU_ADDR_INTR to aggregated Error MPU_ADDR_INTR_ERRAGG1'b1 : Error is Masked1'b0 : Error is Unmasked
  [13] MPU_ADDR_INTR_ERRAGG2_MASK_MPU_CR5A0_AHB_ADDR_ERR2 — Mask Error from MPU_ADDR_INTR to aggregated Error MPU_ADDR_INTR_ERRAGG1'b1 : Error is Masked1'b0 : Error is Unmasked
  [12] MPU_ADDR_INTR_ERRAGG2_MASK_MPU_SCRM2SCRP1_ADDR_ERR2 — Mask Error from MPU_ADDR_INTR to aggregated Error MPU_ADDR_INTR_ERRAGG1'b1 : Error is Masked1'b0 : Error is Unmasked
  [11] MPU_ADDR_INTR_ERRAGG2_MASK_MPU_SCRM2SCRP0_ADDR_ERR2 — Mask Error from MPU_ADDR_INTR to aggregated Error MPU_ADDR_INTR_ERRAGG1'b1 : Error is Masked1'b0 : Error is Unmasked
  [10] MPU_ADDR_INTR_ERRAGG2_MASK_MPU_QSPI_ADDR_ERR2 — Mask Error from MPU_ADDR_INTR to aggregated Error MPU_ADDR_INTR_ERRAGG1'b1 : Error is Masked1'b0 : Error is Unmasked
  [9] MPU_ADDR_INTR_ERRAGG2_MASK_MPU_MBOX_ADDR_ERR2 — Mask Error from MPU_ADDR_INTR to aggregated Error MPU_ADDR_INTR_ERRAGG1'b1 : Error is Masked1'b0 : Error is Unmasked
  [8] MPU_ADDR_INTR_ERRAGG2_MASK_MPU_DTHE_A_ADDR_ERR2 — Mask Error from MPU_ADDR_INTR to aggregated Error MPU_ADDR_INTR_ERRAGG1'b1 : Error is Masked1'b0 : Error is Unmasked
  [7] MPU_ADDR_INTR_ERRAGG2_MASK_MPU_CR5B1_AXIS_ADDR_ERR2 — Mask Error from MPU_ADDR_INTR to aggregated Error MPU_ADDR_INTR_ERRAGG1'b1 : Error is Masked1'b0 : Error is Unmasked
  [6] MPU_ADDR_INTR_ERRAGG2_MASK_MPU_CR5A1_AXIS_ADDR_ERR2 — Mask Error from MPU_ADDR_INTR to aggregated Error MPU_ADDR_INTR_ERRAGG1'b1 : Error is Masked1'b0 : Error is Unmasked
  [5] MPU_ADDR_INTR_ERRAGG2_MASK_MPU_CR5B0_AXIS_ADDR_ERR2 — Mask Error from MPU_ADDR_INTR to aggregated Error MPU_ADDR_INTR_ERRAGG1'b1 : Error is Masked1'b0 : Error is Unmasked
  [4] MPU_ADDR_INTR_ERRAGG2_MASK_MPU_CR5A0_AXIS_ADDR_ERR2 — Mask Error from MPU_ADDR_INTR to aggregated Error MPU_ADDR_INTR_ERRAGG1'b1 : Error is Masked1'b0 : Error is Unmasked
  [3] MPU_ADDR_INTR_ERRAGG2_MASK_MPU_L2_BANK_D_ADDR_ERR2 — Mask Error from MPU_ADDR_INTR to aggregated Error MPU_ADDR_INTR_ERRAGG1'b1 : Error is Masked1'b0 : Error is Unmasked
  [2] MPU_ADDR_INTR_ERRAGG2_MASK_MPU_L2_BANK_C_ADDR_ERR2 — Mask Error from MPU_ADDR_INTR to aggregated Error MPU_ADDR_INTR_ERRAGG1'b1 : Error is Masked1'b0 : Error is Unmasked
  [1] MPU_ADDR_INTR_ERRAGG2_MASK_MPU_L2_BANK_B_ADDR_ERR2 — Mask Error from MPU_ADDR_INTR to aggregated Error MPU_ADDR_INTR_ERRAGG1'b1 : Error is Masked1'b0 : Error is Unmasked
  [0] MPU_ADDR_INTR_ERRAGG2_MASK_MPU_L2_BANK_A_ADDR_ERR2 — Mask Error from MPU_ADDR_INTR to aggregated Error MPU_ADDR_INTR_ERRAGG1'b1 : Error is Masked1'b0 : Error is Unmasked
0xC024 MSS_CTRL_MPU_ADDR_INTR_ERRAGG2_STATUS rw — This register shows the Status of Unmasked MPU Address Errors to R5SS1 Core0 .
  [17] MPU_ADDR_INTR_ERRAGG2_STATUS_MPU_HSM_ADDR_ERR2 — Status of Error from MPU_ADDR_INTR. Set only if Interupt is unmasked in MPU_ADDR_INTR_ERRAGG_MASKWrie 0x1 to clear this Error.
  [16] MPU_ADDR_INTR_ERRAGG2_STATUS_MPU_CR5B1_AHB_ADDR_ERR2 — Status of Error from MPU_ADDR_INTR. Set only if Interupt is unmasked in MPU_ADDR_INTR_ERRAGG_MASKWrie 0x1 to clear this Error.
  [15] MPU_ADDR_INTR_ERRAGG2_STATUS_MPU_CR5A1_AHB_ADDR_ERR2 — Status of Error from MPU_ADDR_INTR. Set only if Interupt is unmasked in MPU_ADDR_INTR_ERRAGG_MASKWrie 0x1 to clear this Error.
  [14] MPU_ADDR_INTR_ERRAGG2_STATUS_MPU_CR5B0_AHB_ADDR_ERR2 — Status of Error from MPU_ADDR_INTR. Set only if Interupt is unmasked in MPU_ADDR_INTR_ERRAGG_MASKWrie 0x1 to clear this Error.
  [13] MPU_ADDR_INTR_ERRAGG2_STATUS_MPU_CR5A0_AHB_ADDR_ERR2 — Status of Error from MPU_ADDR_INTR. Set only if Interupt is unmasked in MPU_ADDR_INTR_ERRAGG_MASKWrie 0x1 to clear this Error.
  [12] MPU_ADDR_INTR_ERRAGG2_STATUS_MPU_SCRM2SCRP1_ADDR_ERR2 — Status of Error from MPU_ADDR_INTR. Set only if Interupt is unmasked in MPU_ADDR_INTR_ERRAGG_MASKWrie 0x1 to clear this Error.
  [11] MPU_ADDR_INTR_ERRAGG2_STATUS_MPU_SCRM2SCRP0_ADDR_ERR2 — Status of Error from MPU_ADDR_INTR. Set only if Interupt is unmasked in MPU_ADDR_INTR_ERRAGG_MASKWrie 0x1 to clear this Error.
  [10] MPU_ADDR_INTR_ERRAGG2_STATUS_MPU_QSPI_ADDR_ERR2 — Status of Error from MPU_ADDR_INTR. Set only if Interupt is unmasked in MPU_ADDR_INTR_ERRAGG_MASKWrie 0x1 to clear this Error.
  [9] MPU_ADDR_INTR_ERRAGG2_STATUS_MPU_MBOX_ADDR_ERR2 — Status of Error from MPU_ADDR_INTR. Set only if Interupt is unmasked in MPU_ADDR_INTR_ERRAGG_MASKWrie 0x1 to clear this Error.
  [8] MPU_ADDR_INTR_ERRAGG2_STATUS_MPU_DTHE_A_ADDR_ERR2 — Status of Error from MPU_ADDR_INTR. Set only if Interupt is unmasked in MPU_ADDR_INTR_ERRAGG_MASKWrie 0x1 to clear this Error.
  [7] MPU_ADDR_INTR_ERRAGG2_STATUS_MPU_CR5B1_AXIS_ADDR_ERR2 — Status of Error from MPU_ADDR_INTR. Set only if Interupt is unmasked in MPU_ADDR_INTR_ERRAGG_MASKWrie 0x1 to clear this Error.
  [6] MPU_ADDR_INTR_ERRAGG2_STATUS_MPU_CR5A1_AXIS_ADDR_ERR2 — Status of Error from MPU_ADDR_INTR. Set only if Interupt is unmasked in MPU_ADDR_INTR_ERRAGG_MASKWrie 0x1 to clear this Error.
  [5] MPU_ADDR_INTR_ERRAGG2_STATUS_MPU_CR5B0_AXIS_ADDR_ERR2 — Status of Error from MPU_ADDR_INTR. Set only if Interupt is unmasked in MPU_ADDR_INTR_ERRAGG_MASKWrie 0x1 to clear this Error.
  [4] MPU_ADDR_INTR_ERRAGG2_STATUS_MPU_CR5A0_AXIS_ADDR_ERR2 — Status of Error from MPU_ADDR_INTR. Set only if Interupt is unmasked in MPU_ADDR_INTR_ERRAGG_MASKWrie 0x1 to clear this Error.
  [3] MPU_ADDR_INTR_ERRAGG2_STATUS_MPU_L2_BANK_D_ADDR_ERR2 — Status of Error from MPU_ADDR_INTR. Set only if Interupt is unmasked in MPU_ADDR_INTR_ERRAGG_MASKWrie 0x1 to clear this Error.
  [2] MPU_ADDR_INTR_ERRAGG2_STATUS_MPU_L2_BANK_C_ADDR_ERR2 — Status of Error from MPU_ADDR_INTR. Set only if Interupt is unmasked in MPU_ADDR_INTR_ERRAGG_MASKWrie 0x1 to clear this Error.
  [1] MPU_ADDR_INTR_ERRAGG2_STATUS_MPU_L2_BANK_B_ADDR_ERR2 — Status of Error from MPU_ADDR_INTR. Set only if Interupt is unmasked in MPU_ADDR_INTR_ERRAGG_MASKWrie 0x1 to clear this Error.
  [0] MPU_ADDR_INTR_ERRAGG2_STATUS_MPU_L2_BANK_A_ADDR_ERR2 — Status of Error from MPU_ADDR_INTR. Set only if Interupt is unmasked in MPU_ADDR_INTR_ERRAGG_MASKWrie 0x1 to clear this Error.
0xC030 MSS_CTRL_MPU_PROT_INTR_ERRAGG2_MASK rw — This register Masks selected interrupt soures from generating MPU Protection Error Interrupt to R5SS1 CORE0 .
  [17] MPU_PROT_INTR_ERRAGG2_MASK_MPU_HSM_PROT_ERR2 — Mask Error from MPU_PROT_INTR to aggregated Error MPU_PROT_INTR_ERRAGG1'b1 : Error is Masked1'b0 : Error is Unmasked
  [16] MPU_PROT_INTR_ERRAGG2_MASK_MPU_CR5B1_AHB_PROT_ERR2 — Mask Error from MPU_PROT_INTR to aggregated Error MPU_PROT_INTR_ERRAGG1'b1 : Error is Masked1'b0 : Error is Unmasked
  [15] MPU_PROT_INTR_ERRAGG2_MASK_MPU_CR5A1_AHB_PROT_ERR2 — Mask Error from MPU_PROT_INTR to aggregated Error MPU_PROT_INTR_ERRAGG1'b1 : Error is Masked1'b0 : Error is Unmasked
  [14] MPU_PROT_INTR_ERRAGG2_MASK_MPU_CR5B0_AHB_PROT_ERR2 — Mask Error from MPU_PROT_INTR to aggregated Error MPU_PROT_INTR_ERRAGG1'b1 : Error is Masked1'b0 : Error is Unmasked
  [13] MPU_PROT_INTR_ERRAGG2_MASK_MPU_CR5A0_AHB_PROT_ERR2 — Mask Error from MPU_PROT_INTR to aggregated Error MPU_PROT_INTR_ERRAGG1'b1 : Error is Masked1'b0 : Error is Unmasked
  [12] MPU_PROT_INTR_ERRAGG2_MASK_MPU_SCRM2SCRP1_PROT_ERR2 — Mask Error from MPU_PROT_INTR to aggregated Error MPU_PROT_INTR_ERRAGG1'b1 : Error is Masked1'b0 : Error is Unmasked
  [11] MPU_PROT_INTR_ERRAGG2_MASK_MPU_SCRM2SCRP0_PROT_ERR2 — Mask Error from MPU_PROT_INTR to aggregated Error MPU_PROT_INTR_ERRAGG1'b1 : Error is Masked1'b0 : Error is Unmasked
  [10] MPU_PROT_INTR_ERRAGG2_MASK_MPU_QSPI_PROT_ERR2 — Mask Error from MPU_PROT_INTR to aggregated Error MPU_PROT_INTR_ERRAGG1'b1 : Error is Masked1'b0 : Error is Unmasked
  [9] MPU_PROT_INTR_ERRAGG2_MASK_MPU_MBOX_PROT_ERR2 — Mask Error from MPU_PROT_INTR to aggregated Error MPU_PROT_INTR_ERRAGG1'b1 : Error is Masked1'b0 : Error is Unmasked
  [8] MPU_PROT_INTR_ERRAGG2_MASK_MPU_DTHE_A_PROT_ERR2 — Mask Error from MPU_PROT_INTR to aggregated Error MPU_PROT_INTR_ERRAGG1'b1 : Error is Masked1'b0 : Error is Unmasked
  [7] MPU_PROT_INTR_ERRAGG2_MASK_MPU_CR5B1_AXIS_PROT_ERR2 — Mask Error from MPU_PROT_INTR to aggregated Error MPU_PROT_INTR_ERRAGG1'b1 : Error is Masked1'b0 : Error is Unmasked
  [6] MPU_PROT_INTR_ERRAGG2_MASK_MPU_CR5A1_AXIS_PROT_ERR2 — Mask Error from MPU_PROT_INTR to aggregated Error MPU_PROT_INTR_ERRAGG1'b1 : Error is Masked1'b0 : Error is Unmasked
  [5] MPU_PROT_INTR_ERRAGG2_MASK_MPU_CR5B0_AXIS_PROT_ERR2 — Mask Error from MPU_PROT_INTR to aggregated Error MPU_PROT_INTR_ERRAGG1'b1 : Error is Masked1'b0 : Error is Unmasked
  [4] MPU_PROT_INTR_ERRAGG2_MASK_MPU_CR5A0_AXIS_PROT_ERR2 — Mask Error from MPU_PROT_INTR to aggregated Error MPU_PROT_INTR_ERRAGG1'b1 : Error is Masked1'b0 : Error is Unmasked
  [3] MPU_PROT_INTR_ERRAGG2_MASK_MPU_L2_BANK_D_PROT_ERR2 — Mask Error from MPU_PROT_INTR to aggregated Error MPU_PROT_INTR_ERRAGG1'b1 : Error is Masked1'b0 : Error is Unmasked
  [2] MPU_PROT_INTR_ERRAGG2_MASK_MPU_L2_BANK_C_PROT_ERR2 — Mask Error from MPU_PROT_INTR to aggregated Error MPU_PROT_INTR_ERRAGG1'b1 : Error is Masked1'b0 : Error is Unmasked
  [1] MPU_PROT_INTR_ERRAGG2_MASK_MPU_L2_BANK_B_PROT_ERR2 — Mask Error from MPU_PROT_INTR to aggregated Error MPU_PROT_INTR_ERRAGG1'b1 : Error is Masked1'b0 : Error is Unmasked
  [0] MPU_PROT_INTR_ERRAGG2_MASK_MPU_L2_BANK_A_PROT_ERR2 — Mask Error from MPU_PROT_INTR to aggregated Error MPU_PROT_INTR_ERRAGG1'b1 : Error is Masked1'b0 : Error is Unmasked
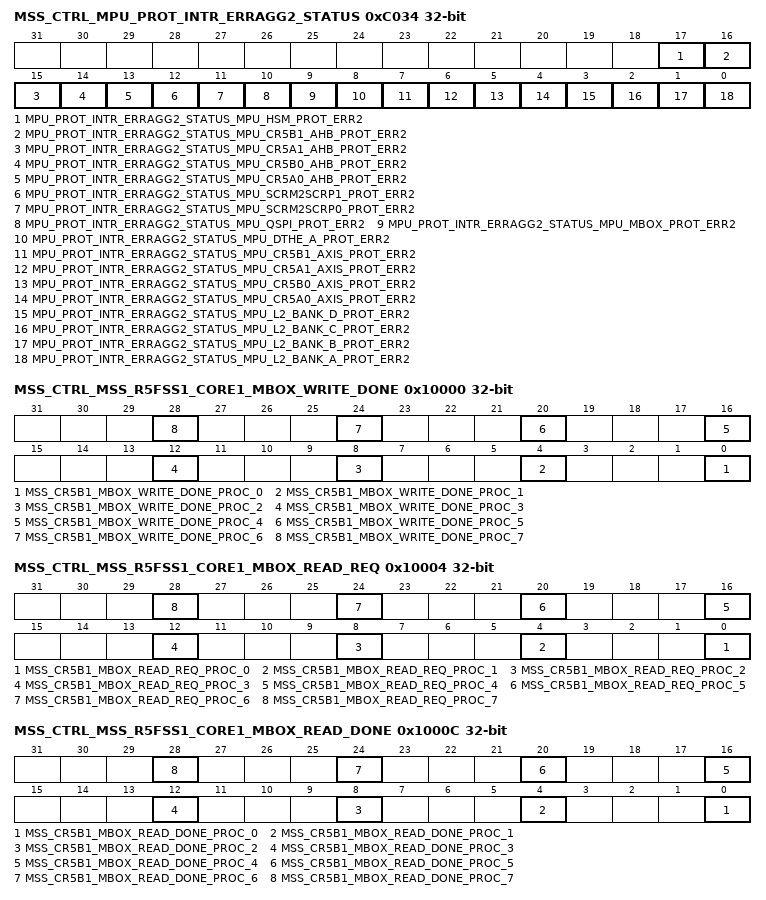
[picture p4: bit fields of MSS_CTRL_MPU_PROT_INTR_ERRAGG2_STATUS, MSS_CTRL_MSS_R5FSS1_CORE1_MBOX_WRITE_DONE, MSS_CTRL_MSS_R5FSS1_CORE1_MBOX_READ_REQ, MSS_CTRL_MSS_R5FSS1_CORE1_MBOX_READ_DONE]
0xC034 MSS_CTRL_MPU_PROT_INTR_ERRAGG2_STATUS rw — This register shows the Status of Unmasked MPU Protection Errors to R5SS1 Core0 .
  [17] MPU_PROT_INTR_ERRAGG2_STATUS_MPU_HSM_PROT_ERR2 — Status of Error from MPU_PROT_INTR. Set only if Interupt is unmasked in MPU_PROT_INTR_ERRAGG_MASKWrie 0x1 to clear this Error.
  [16] MPU_PROT_INTR_ERRAGG2_STATUS_MPU_CR5B1_AHB_PROT_ERR2 — Status of Error from MPU_PROT_INTR. Set only if Interupt is unmasked in MPU_PROT_INTR_ERRAGG_MASKWrie 0x1 to clear this Error.
  [15] MPU_PROT_INTR_ERRAGG2_STATUS_MPU_CR5A1_AHB_PROT_ERR2 — Status of Error from MPU_PROT_INTR. Set only if Interupt is unmasked in MPU_PROT_INTR_ERRAGG_MASKWrie 0x1 to clear this Error.
  [14] MPU_PROT_INTR_ERRAGG2_STATUS_MPU_CR5B0_AHB_PROT_ERR2 — Status of Error from MPU_PROT_INTR. Set only if Interupt is unmasked in MPU_PROT_INTR_ERRAGG_MASKWrie 0x1 to clear this Error.
  [13] MPU_PROT_INTR_ERRAGG2_STATUS_MPU_CR5A0_AHB_PROT_ERR2 — Status of Error from MPU_PROT_INTR. Set only if Interupt is unmasked in MPU_PROT_INTR_ERRAGG_MASKWrie 0x1 to clear this Error.
  [12] MPU_PROT_INTR_ERRAGG2_STATUS_MPU_SCRM2SCRP1_PROT_ERR2 — Status of Error from MPU_PROT_INTR. Set only if Interupt is unmasked in MPU_PROT_INTR_ERRAGG_MASKWrie 0x1 to clear this Error.
  [11] MPU_PROT_INTR_ERRAGG2_STATUS_MPU_SCRM2SCRP0_PROT_ERR2 — Status of Error from MPU_PROT_INTR. Set only if Interupt is unmasked in MPU_PROT_INTR_ERRAGG_MASKWrie 0x1 to clear this Error.
  [10] MPU_PROT_INTR_ERRAGG2_STATUS_MPU_QSPI_PROT_ERR2 — Status of Error from MPU_PROT_INTR. Set only if Interupt is unmasked in MPU_PROT_INTR_ERRAGG_MASKWrie 0x1 to clear this Error.
  [9] MPU_PROT_INTR_ERRAGG2_STATUS_MPU_MBOX_PROT_ERR2 — Status of Error from MPU_PROT_INTR. Set only if Interupt is unmasked in MPU_PROT_INTR_ERRAGG_MASKWrie 0x1 to clear this Error.
  [8] MPU_PROT_INTR_ERRAGG2_STATUS_MPU_DTHE_A_PROT_ERR2 — Status of Error from MPU_PROT_INTR. Set only if Interupt is unmasked in MPU_PROT_INTR_ERRAGG_MASKWrie 0x1 to clear this Error.
  [7] MPU_PROT_INTR_ERRAGG2_STATUS_MPU_CR5B1_AXIS_PROT_ERR2 — Status of Error from MPU_PROT_INTR. Set only if Interupt is unmasked in MPU_PROT_INTR_ERRAGG_MASKWrie 0x1 to clear this Error.
  [6] MPU_PROT_INTR_ERRAGG2_STATUS_MPU_CR5A1_AXIS_PROT_ERR2 — Status of Error from MPU_PROT_INTR. Set only if Interupt is unmasked in MPU_PROT_INTR_ERRAGG_MASKWrie 0x1 to clear this Error.
  [5] MPU_PROT_INTR_ERRAGG2_STATUS_MPU_CR5B0_AXIS_PROT_ERR2 — Status of Error from MPU_PROT_INTR. Set only if Interupt is unmasked in MPU_PROT_INTR_ERRAGG_MASKWrie 0x1 to clear this Error.
  [4] MPU_PROT_INTR_ERRAGG2_STATUS_MPU_CR5A0_AXIS_PROT_ERR2 — Status of Error from MPU_PROT_INTR. Set only if Interupt is unmasked in MPU_PROT_INTR_ERRAGG_MASKWrie 0x1 to clear this Error.
  [3] MPU_PROT_INTR_ERRAGG2_STATUS_MPU_L2_BANK_D_PROT_ERR2 — Status of Error from MPU_PROT_INTR. Set only if Interupt is unmasked in MPU_PROT_INTR_ERRAGG_MASKWrie 0x1 to clear this Error.
  [2] MPU_PROT_INTR_ERRAGG2_STATUS_MPU_L2_BANK_C_PROT_ERR2 — Status of Error from MPU_PROT_INTR. Set only if Interupt is unmasked in MPU_PROT_INTR_ERRAGG_MASKWrie 0x1 to clear this Error.
  [1] MPU_PROT_INTR_ERRAGG2_STATUS_MPU_L2_BANK_B_PROT_ERR2 — Status of Error from MPU_PROT_INTR. Set only if Interupt is unmasked in MPU_PROT_INTR_ERRAGG_MASKWrie 0x1 to clear this Error.
  [0] MPU_PROT_INTR_ERRAGG2_STATUS_MPU_L2_BANK_A_PROT_ERR2 — Status of Error from MPU_PROT_INTR. Set only if Interupt is unmasked in MPU_PROT_INTR_ERRAGG_MASKWrie 0x1 to clear this Error.
0x10000 MSS_CTRL_MSS_R5FSS1_CORE1_MBOX_WRITE_DONE rw — This register is used by R5SS1 Core 1 to generate Mailbox interrupt to Recipent CPU.
  [4n] MSS_CR5B1_MBOX_WRITE_DONE_PROC_{n} (n=0..7) — Write pulse bit field:This register should be written once finishing Writing into the mailbox memory of processor {n}
0x10004 MSS_CTRL_MSS_R5FSS1_CORE1_MBOX_READ_REQ rw — This register is used by R5SS1 Core 1 to know the Sender of Mailbox Interrupt as well as clear it.
  [4n] MSS_CR5B1_MBOX_READ_REQ_PROC_{n} (n=0..7) — This is request from processor {n} to mss_CR5B. Requesting it to read from mailbox.
0x10008 MSS_CTRL_MSS_R5FSS1_CORE1_MBOX_READ_DONE_ACK rw — This register is used by R5SS1 Core 1 to generate Mailbox Read acknowledgement to the Sender CPU.
  [7:0] MSS_CR5B1_MBOX_READ_DONE_ACK_PROC — Write pulse bit field:For bits 0 to7:Wrting1'b1 : Generates pulse interrupt to corresponding proc from MSS_CR5
0x1000C MSS_CTRL_MSS_R5FSS1_CORE1_MBOX_READ_DONE rw — This register is used by R5SS1 Core 1 to know that the Receiver CPU has read the Mailbox and Acked. It is also used to clear the Read Done Interrupt.
  [4n] MSS_CR5B1_MBOX_READ_DONE_PROC_{n} (n=0..7) — This register should be written once finishing Reading from proc{n}'s mailbox written by CR5B
0x10010 MSS_CTRL_MSS_SW_INT_R5SS1_CORE1 rw — This Register is used to generate a S/W Triggered Interrupt to R5SS1 Core1.
  [0] MSS_SW_INT_R5SS1_CORE1_PULSE — Write_pulse bit field:Writing 1'b1 to each bit will trigger MSS_SW_INT respectively to CR5A/B.
